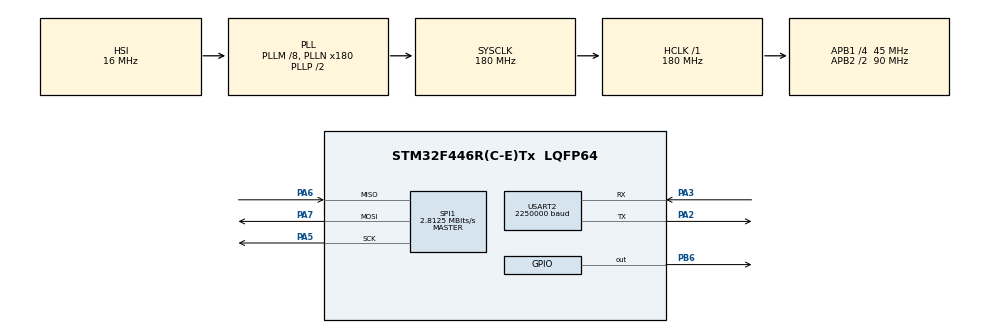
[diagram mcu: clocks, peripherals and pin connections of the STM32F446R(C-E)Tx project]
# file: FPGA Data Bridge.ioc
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Dma.Request0=USART2_RX
Dma.Request1=USART2_TX
Dma.Request2=SPI1_RX
Dma.Request3=SPI1_TX
Dma.SPI1_RX.2.Direction=DMA_PERIPH_TO_MEMORY
Dma.SPI1_RX.2.FIFOMode=DMA_FIFOMODE_DISABLE
Dma.SPI1_RX.2.Instance=DMA2_Stream0
Dma.SPI1_RX.2.MemDataAlignment=DMA_MDATAALIGN_HALFWORD
Dma.SPI1_RX.2.MemInc=DMA_MINC_ENABLE
Dma.SPI1_RX.2.Mode=DMA_NORMAL
Dma.SPI1_RX.2.PeriphDataAlignment=DMA_PDATAALIGN_HALFWORD
Dma.SPI1_RX.2.PeriphInc=DMA_PINC_DISABLE
Dma.SPI1_RX.2.Priority=DMA_PRIORITY_LOW
Dma.SPI1_TX.3.Direction=DMA_MEMORY_TO_PERIPH
Dma.SPI1_TX.3.FIFOMode=DMA_FIFOMODE_DISABLE
Dma.SPI1_TX.3.Instance=DMA2_Stream3
Dma.SPI1_TX.3.MemDataAlignment=DMA_MDATAALIGN_HALFWORD
Dma.SPI1_TX.3.MemInc=DMA_MINC_ENABLE
Dma.SPI1_TX.3.Mode=DMA_NORMAL
Dma.SPI1_TX.3.PeriphDataAlignment=DMA_PDATAALIGN_HALFWORD
Dma.SPI1_TX.3.PeriphInc=DMA_PINC_DISABLE
Dma.SPI1_TX.3.Priority=DMA_PRIORITY_LOW
Dma.USART2_RX.0.Direction=DMA_PERIPH_TO_MEMORY
Dma.USART2_RX.0.FIFOMode=DMA_FIFOMODE_DISABLE
Dma.USART2_RX.0.Instance=DMA1_Stream5
Dma.USART2_RX.0.MemDataAlignment=DMA_MDATAALIGN_BYTE
Dma.USART2_RX.0.MemInc=DMA_MINC_ENABLE
Dma.USART2_RX.0.Mode=DMA_NORMAL
Dma.USART2_RX.0.PeriphDataAlignment=DMA_PDATAALIGN_BYTE
Dma.USART2_RX.0.PeriphInc=DMA_PINC_DISABLE
Dma.USART2_RX.0.Priority=DMA_PRIORITY_LOW
Dma.USART2_TX.1.Direction=DMA_MEMORY_TO_PERIPH
Dma.USART2_TX.1.FIFOMode=DMA_FIFOMODE_DISABLE
Dma.USART2_TX.1.Instance=DMA1_Stream6
Dma.USART2_TX.1.MemDataAlignment=DMA_MDATAALIGN_BYTE
Dma.USART2_TX.1.MemInc=DMA_MINC_ENABLE
Dma.USART2_TX.1.Mode=DMA_NORMAL
Dma.USART2_TX.1.PeriphDataAlignment=DMA_PDATAALIGN_BYTE
Dma.USART2_TX.1.PeriphInc=DMA_PINC_DISABLE
Dma.USART2_TX.1.Priority=DMA_PRIORITY_LOW
Mcu.Family=STM32F4
Mcu.Name=STM32F446R(C-E)Tx
Mcu.Package=LQFP64
NVIC.DMA1_Stream5_IRQn=true\:0\:0\:false\:false\:true\:false\:true\:true
NVIC.DMA1_Stream6_IRQn=true\:0\:0\:false\:false\:true\:false\:true\:true
NVIC.DMA2_Stream0_IRQn=true\:0\:0\:false\:false\:true\:false\:true\:true
NVIC.DMA2_Stream3_IRQn=true\:0\:0\:false\:false\:true\:false\:true\:true
NVIC.PriorityGroup=NVIC_PRIORITYGROUP_4
NVIC.SPI1_IRQn=true\:0\:0\:false\:false\:true\:true\:true\:true
NVIC.USART2_IRQn=true\:0\:0\:false\:false\:true\:true\:true\:true
PA2.Mode=Asynchronous
PA2.Signal=USART2_TX
PA3.Mode=Asynchronous
PA3.Signal=USART2_RX
PA5.Mode=Full_Duplex_Master
PA5.Signal=SPI1_SCK
PA6.Mode=Full_Duplex_Master
PA6.Signal=SPI1_MISO
PA7.Mode=Full_Duplex_Master
PA7.Signal=SPI1_MOSI
PB6.Signal=GPIO_Output
ProjectManager.HeapSize=0x200
ProjectManager.StackSize=0x400
ProjectManager.TargetToolchain=STM32CubeIDE
RCC.AHBFreq_Value=180000000
RCC.APB1CLKDivider=RCC_HCLK_DIV4
RCC.APB1Freq_Value=45000000
RCC.APB1TimFreq_Value=90000000
RCC.APB2CLKDivider=RCC_HCLK_DIV2
RCC.APB2Freq_Value=90000000
RCC.APB2TimFreq_Value=180000000
RCC.CortexFreq_Value=180000000
RCC.HCLKFreq_Value=180000000
RCC.PLLM=8
RCC.PLLN=180
RCC.SYSCLKFreq_VALUE=180000000
RCC.SYSCLKSource=RCC_SYSCLKSOURCE_PLLCLK
RCC.USBFreq_Value=180000000
RCC.VCOOutputFreq_Value=360000000
SPI1.BaudRatePrescaler=SPI_BAUDRATEPRESCALER_32
SPI1.CalculateBaudRate=2.8125 MBits/s
SPI1.DataSize=SPI_DATASIZE_16BIT
SPI1.Direction=SPI_DIRECTION_2LINES
SPI1.Mode=SPI_MODE_MASTER
SPI1.VirtualType=VM_MASTER
USART2.BaudRate=2250000
USART2.VirtualMode=VM_ASYNC
board=custom

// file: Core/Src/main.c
/* USER CODE BEGIN Header */
/**
  ******************************************************************************
  * @file           : main.c
  * @brief          : Main program body
  ******************************************************************************
  * @attention
  *
  * Copyright (c) 2026 STMicroelectronics.
  * All rights reserved.
  *
  * This software is licensed under terms that can be found in the LICENSE file
  * in the root directory of this software component.
  * If no LICENSE file comes with this software, it is provided AS-IS.
  *
  ******************************************************************************
  */
/* USER CODE END Header */
#include "main.h"

SPI_HandleTypeDef hspi1;
DMA_HandleTypeDef hdma_spi1_rx;
DMA_HandleTypeDef hdma_spi1_tx;

UART_HandleTypeDef huart2;
DMA_HandleTypeDef hdma_usart2_rx;
DMA_HandleTypeDef hdma_usart2_tx;

void SystemClock_Config(void);
static void MX_GPIO_Init(void);
static void MX_DMA_Init(void);
static void MX_USART2_UART_Init(void);
static void MX_SPI1_Init(void);
/* USER CODE BEGIN PFP */
void AudioRelay_Init(void);   /* defined in audio_relay.c */
/* USER CODE END PFP */

int main(void)
{

  /* MCU Configuration--------------------------------------------------------*/

  /* Reset of all peripherals, Initializes the Flash interface and the Systick. */
  HAL_Init();

  /* Configure the system clock */
  SystemClock_Config();

  /* Initialize all configured peripherals */
  MX_GPIO_Init();
  MX_DMA_Init();
  MX_USART2_UART_Init();
  MX_SPI1_Init();
  /* USER CODE BEGIN 2 */
  AudioRelay_Init();   /* arms UART RX DMA; everything after this is interrupt-driven */
  /* USER CODE END 2 */

  /* Infinite loop */
  while (1)
  {

  }
}

void SystemClock_Config(void)
{
  RCC_OscInitTypeDef RCC_OscInitStruct = {0};
  RCC_ClkInitTypeDef RCC_ClkInitStruct = {0};

  /** Configure the main internal regulator output voltage
  */
  __HAL_RCC_PWR_CLK_ENABLE();
  __HAL_PWR_VOLTAGESCALING_CONFIG(PWR_REGULATOR_VOLTAGE_SCALE1);

  /** Initializes the RCC Oscillators according to the specified parameters
  * in the RCC_OscInitTypeDef structure.
  */
  RCC_OscInitStruct.OscillatorType = RCC_OSCILLATORTYPE_HSI;
  RCC_OscInitStruct.HSIState = RCC_HSI_ON;
  RCC_OscInitStruct.HSICalibrationValue = RCC_HSICALIBRATION_DEFAULT;
  RCC_OscInitStruct.PLL.PLLState = RCC_PLL_ON;
  RCC_OscInitStruct.PLL.PLLSource = RCC_PLLSOURCE_HSI;
  RCC_OscInitStruct.PLL.PLLM = 8;
  RCC_OscInitStruct.PLL.PLLN = 180;
  RCC_OscInitStruct.PLL.PLLP = RCC_PLLP_DIV2;
  RCC_OscInitStruct.PLL.PLLQ = 2;
  RCC_OscInitStruct.PLL.PLLR = 2;
  if (HAL_RCC_OscConfig(&RCC_OscInitStruct) != HAL_OK)
  {
    Error_Handler();
  }

  /** Activate the Over-Drive mode
  */
  if (HAL_PWREx_EnableOverDrive() != HAL_OK)
  {
    Error_Handler();
  }

  /** Initializes the CPU, AHB and APB buses clocks
  */
  RCC_ClkInitStruct.ClockType = RCC_CLOCKTYPE_HCLK|RCC_CLOCKTYPE_SYSCLK
                              |RCC_CLOCKTYPE_PCLK1|RCC_CLOCKTYPE_PCLK2;
  RCC_ClkInitStruct.SYSCLKSource = RCC_SYSCLKSOURCE_PLLCLK;
  RCC_ClkInitStruct.AHBCLKDivider = RCC_SYSCLK_DIV1;
  RCC_ClkInitStruct.APB1CLKDivider = RCC_HCLK_DIV4;
  RCC_ClkInitStruct.APB2CLKDivider = RCC_HCLK_DIV2;

  if (HAL_RCC_ClockConfig(&RCC_ClkInitStruct, FLASH_LATENCY_5) != HAL_OK)
  {
    Error_Handler();
  }
}

static void MX_SPI1_Init(void)
{

  /* SPI1 parameter configuration*/
  hspi1.Instance = SPI1;
  hspi1.Init.Mode = SPI_MODE_MASTER;
  hspi1.Init.Direction = SPI_DIRECTION_2LINES;
  hspi1.Init.DataSize = SPI_DATASIZE_16BIT;
  hspi1.Init.CLKPolarity = SPI_POLARITY_LOW;
  hspi1.Init.CLKPhase = SPI_PHASE_1EDGE;
  hspi1.Init.NSS = SPI_NSS_SOFT;
  hspi1.Init.BaudRatePrescaler = SPI_BAUDRATEPRESCALER_32;
  hspi1.Init.FirstBit = SPI_FIRSTBIT_MSB;
  hspi1.Init.TIMode = SPI_TIMODE_DISABLE;
  hspi1.Init.CRCCalculation = SPI_CRCCALCULATION_DISABLE;
  hspi1.Init.CRCPolynomial = 10;
  if (HAL_SPI_Init(&hspi1) != HAL_OK)
  {
    Error_Handler();
  }

}

static void MX_USART2_UART_Init(void)
{

  huart2.Instance = USART2;
  huart2.Init.BaudRate = 2250000;
  huart2.Init.WordLength = UART_WORDLENGTH_8B;
  huart2.Init.StopBits = UART_STOPBITS_1;
  huart2.Init.Parity = UART_PARITY_NONE;
  huart2.Init.Mode = UART_MODE_TX_RX;
  huart2.Init.HwFlowCtl = UART_HWCONTROL_NONE;
  huart2.Init.OverSampling = UART_OVERSAMPLING_16;
  if (HAL_UART_Init(&huart2) != HAL_OK)
  {
    Error_Handler();
  }

}

static void MX_DMA_Init(void)
{

  /* DMA controller clock enable */
  __HAL_RCC_DMA1_CLK_ENABLE();
  __HAL_RCC_DMA2_CLK_ENABLE();

  /* DMA interrupt init */
  /* DMA1_Stream5_IRQn interrupt configuration */
  HAL_NVIC_SetPriority(DMA1_Stream5_IRQn, 0, 0);
  HAL_NVIC_EnableIRQ(DMA1_Stream5_IRQn);
  /* DMA1_Stream6_IRQn interrupt configuration */
  HAL_NVIC_SetPriority(DMA1_Stream6_IRQn, 0, 0);
  HAL_NVIC_EnableIRQ(DMA1_Stream6_IRQn);
  /* DMA2_Stream0_IRQn interrupt configuration */
  HAL_NVIC_SetPriority(DMA2_Stream0_IRQn, 0, 0);
  HAL_NVIC_EnableIRQ(DMA2_Stream0_IRQn);
  /* DMA2_Stream3_IRQn interrupt configuration */
  HAL_NVIC_SetPriority(DMA2_Stream3_IRQn, 0, 0);
  HAL_NVIC_EnableIRQ(DMA2_Stream3_IRQn);

}

static void MX_GPIO_Init(void)
{
  GPIO_InitTypeDef GPIO_InitStruct = {0};

  /* GPIO Ports Clock Enable */
  __HAL_RCC_GPIOA_CLK_ENABLE();
  __HAL_RCC_GPIOB_CLK_ENABLE();

  /*Configure GPIO pin Output Level */
  HAL_GPIO_WritePin(GPIOB, GPIO_PIN_6, GPIO_PIN_RESET);

  /*Configure GPIO pin : PB6 */
  GPIO_InitStruct.Pin = GPIO_PIN_6;
  GPIO_InitStruct.Mode = GPIO_MODE_OUTPUT_PP;
  GPIO_InitStruct.Pull = GPIO_NOPULL;
  GPIO_InitStruct.Speed = GPIO_SPEED_FREQ_LOW;
  HAL_GPIO_Init(GPIOB, &GPIO_InitStruct);

}

void Error_Handler(void)
{
  __disable_irq();
  while (1)
  {
  }
}
